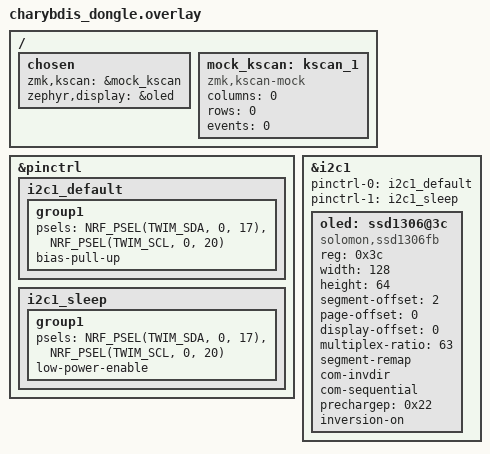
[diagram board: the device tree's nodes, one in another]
#include "charybdis.dtsi"
#include "split_input_common.dtsi"
#include <dt-bindings/pinctrl/nrf-pinctrl.h>

&pinctrl {
    i2c1_default: i2c1_default {
        group1 {
            psels = <NRF_PSEL(TWIM_SDA, 0, 17)>,  
                    <NRF_PSEL(TWIM_SCL, 0, 20)>;  
            bias-pull-up;
        };
    };

    i2c1_sleep: i2c1_sleep {
        group1 {
            psels = <NRF_PSEL(TWIM_SDA, 0, 17)>,
                    <NRF_PSEL(TWIM_SCL, 0, 20)>;
            low-power-enable;
        };
    };
};

/ {
    chosen {
        zmk,kscan = &mock_kscan;
    };

    mock_kscan: kscan_1 {
        compatible = "zmk,kscan-mock";
        columns = <0>;
        rows = <0>;
        events = <0>;
    };
};

/ {
    chosen {
        zephyr,display = &oled;
    };
};

&i2c1 {
    status = "okay";
    pinctrl-0 = <&i2c1_default>;
    pinctrl-1 = <&i2c1_sleep>;
    pinctrl-names = "default", "sleep";

    oled: ssd1306@3c {
        compatible = "solomon,ssd1306fb";
        reg = <0x3c>;
        width = <128>;
        height = <64>;
        segment-offset = <2>;   
        page-offset = <0>;
        display-offset = <0>;
        multiplex-ratio = <63>;
        segment-remap;
        com-invdir;
        com-sequential;
        prechargep = <0x22>;
        inversion-on;
    };
};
